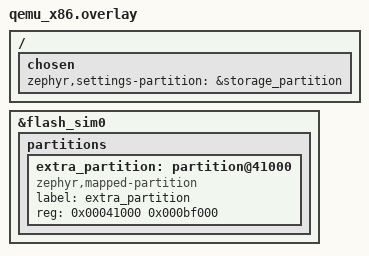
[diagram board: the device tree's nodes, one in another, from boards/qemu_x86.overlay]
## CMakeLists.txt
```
# SPDX-FileCopyrightText: FoBE Studio
# SPDX-License-Identifier: Apache-2.0

cmake_minimum_required(VERSION 3.20.0)
find_package(Zephyr REQUIRED HINTS $ENV{ZEPHYR_BASE})
project(mbs_desktop_mba_lifecycle_test)

include(${CMAKE_CURRENT_LIST_DIR}/app.cmake)
```

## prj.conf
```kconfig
# SPDX-FileCopyrightText: FoBE Studio
# SPDX-License-Identifier: Apache-2.0

CONFIG_ZTEST=y
CONFIG_ASSERT=y
CONFIG_LOG=y
CONFIG_MBS=y
CONFIG_MBS_LLEXT=y
CONFIG_MBS_LLEXT_BRIDGE=n
CONFIG_MBS_LLEXT_DEFAULT_ENABLED=y
CONFIG_MBS_LLEXT_APP_HEAP_RESERVE_SIZE=32768
CONFIG_MBS_LLEXT_APP_MAX_HEAP_SIZE=32768
CONFIG_LLEXT=y
CONFIG_LLEXT_HEAP_DYNAMIC=y
CONFIG_DISPLAY=y
CONFIG_U8G2=y
CONFIG_ZUI=y
CONFIG_DYNAMIC_THREAD=y
CONFIG_THREAD_STACK_INFO=y

CONFIG_FILE_SYSTEM=y
CONFIG_FILE_SYSTEM_LITTLEFS=y
CONFIG_FS_LITTLEFS_FMP_DEV=y
CONFIG_FLASH=y
CONFIG_FLASH_MAP=y
CONFIG_FLASH_SIMULATOR=y
CONFIG_SETTINGS=y
CONFIG_SETTINGS_ZMS=y
CONFIG_ZMS=y

CONFIG_HEAP_MEM_POOL_SIZE=196608
CONFIG_MAIN_STACK_SIZE=4096
CONFIG_SYSTEM_WORKQUEUE_STACK_SIZE=4096
CONFIG_ZTEST_STACK_SIZE=4096

CONFIG_JSON_LIBRARY=y
CONFIG_PSA_CRYPTO=y
CONFIG_PSA_WANT_ALG_SHA_256=y
```

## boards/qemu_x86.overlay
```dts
&flash_sim0 {
	partitions {
		extra_partition: partition@41000 {
			compatible = "zephyr,mapped-partition";
			label = "extra_partition";
			reg = <0x00041000 0x000bf000>;
		};
	};
};

/ {
	chosen {
		zephyr,settings-partition = &storage_partition;
	};
};
```

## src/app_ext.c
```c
/* SPDX-FileCopyrightText: FoBE Studio */
/* SPDX-License-Identifier: Apache-2.0 */

#include <zephyr/llext/symbol.h>
#include <llext/metadata.h>

extern void mba_test_run(void *args);

static const struct mbs_llext_app_metadata metadata
	MBS_LLEXT_APP_METADATA_ATTR = {
	.magic = MBS_LLEXT_APP_METADATA_MAGIC,
	.metadata_version = MBS_LLEXT_APP_METADATA_VERSION,
	.size = sizeof(struct mbs_llext_app_metadata),
	.stack_size = 1024U,
	.heap_size = 32768U,
	.id = "mba-lifecycle",
	.name = "MBA lifecycle",
	.app_version = "1.0.0",
#if defined(TEST_BAD_ENTRY)
	.entry_point_symbol = "missing_entry",
#else
	.entry_point_symbol = "mba_test_entry",
#endif
	.edk_version = "0.1.0",
	.target = CONFIG_BOARD_TARGET,
};

void mba_test_entry(void *args)
{
	mba_test_run(args);
}
EXPORT_SYMBOL(mba_test_entry);
```

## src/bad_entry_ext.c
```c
/* SPDX-FileCopyrightText: FoBE Studio */
/* SPDX-License-Identifier: Apache-2.0 */

#define TEST_BAD_ENTRY 1
#include "app_ext.c"
```
